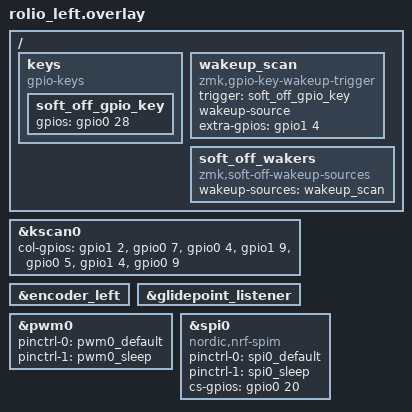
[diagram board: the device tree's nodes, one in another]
/*
 * Rolio left half — split central, display, roller.
 *
 * Column order is outer pinky -> inner. Column 6 (P0.09) is not a keycap
 * column: it holds only the roller's push switch and the wide thumb key.
 *
 * SPDX-License-Identifier: MIT
 */

#include "rolio.dtsi"

/************************************************/
/*           Key Matrix configuration           */
/************************************************/
&kscan0 {
    col-gpios
        = <&gpio1 2 GPIO_ACTIVE_HIGH>   // COL0  outer pinky
        , <&gpio0 7 GPIO_ACTIVE_HIGH>   // COL1
        , <&gpio0 4 GPIO_ACTIVE_HIGH>   // COL2
        , <&gpio1 9 GPIO_ACTIVE_HIGH>   // COL3
        , <&gpio0 5 GPIO_ACTIVE_HIGH>   // COL4
        , <&gpio1 4 GPIO_ACTIVE_HIGH>   // COL5  index
        , <&gpio0 9 GPIO_ACTIVE_HIGH>   // COL6  roller click + wide thumb
        ;
};

&encoder_left {
    status = "okay";
};

/* The central owns the pointer pipeline for the right half's trackpad. */
&glidepoint_listener {
    status = "okay";
};

/************************************************/
/*        Underglow power configuration         */
/************************************************/
&pwm0 {
    status = "okay";
    pinctrl-0 = <&pwm0_default>;
    pinctrl-1 = <&pwm0_sleep>;
    pinctrl-names = "default", "sleep";
};

/************************************************/
/*             Display configuration            */
/************************************************/
/* The vista508 shield hangs its panel off this label. */
vista508_spi: &spi0 {
    compatible = "nordic,nrf-spim";
    pinctrl-0 = <&spi0_default>;
    pinctrl-1 = <&spi0_sleep>;
    pinctrl-names = "default", "sleep";
    cs-gpios = <&gpio0 20 GPIO_ACTIVE_HIGH>;
};

/************************************************/
/*            Soft off configuration            */
/************************************************/
/ {
    keys {
        compatible = "gpio-keys";
        soft_off_gpio_key: soft_off_gpio_key {
            gpios = <&gpio0 28 (GPIO_ACTIVE_HIGH | GPIO_PULL_DOWN)>; // ROW3
        };
    };
    wakeup_scan: wakeup_scan {
        compatible = "zmk,gpio-key-wakeup-trigger";
        trigger = <&soft_off_gpio_key>;
        wakeup-source;
        extra-gpios = <&gpio1 4 GPIO_ACTIVE_HIGH>; // COL5
    };
    soft_off_wakers {
        compatible = "zmk,soft-off-wakeup-sources";
        wakeup-sources = <&wakeup_scan>;
    };
};
